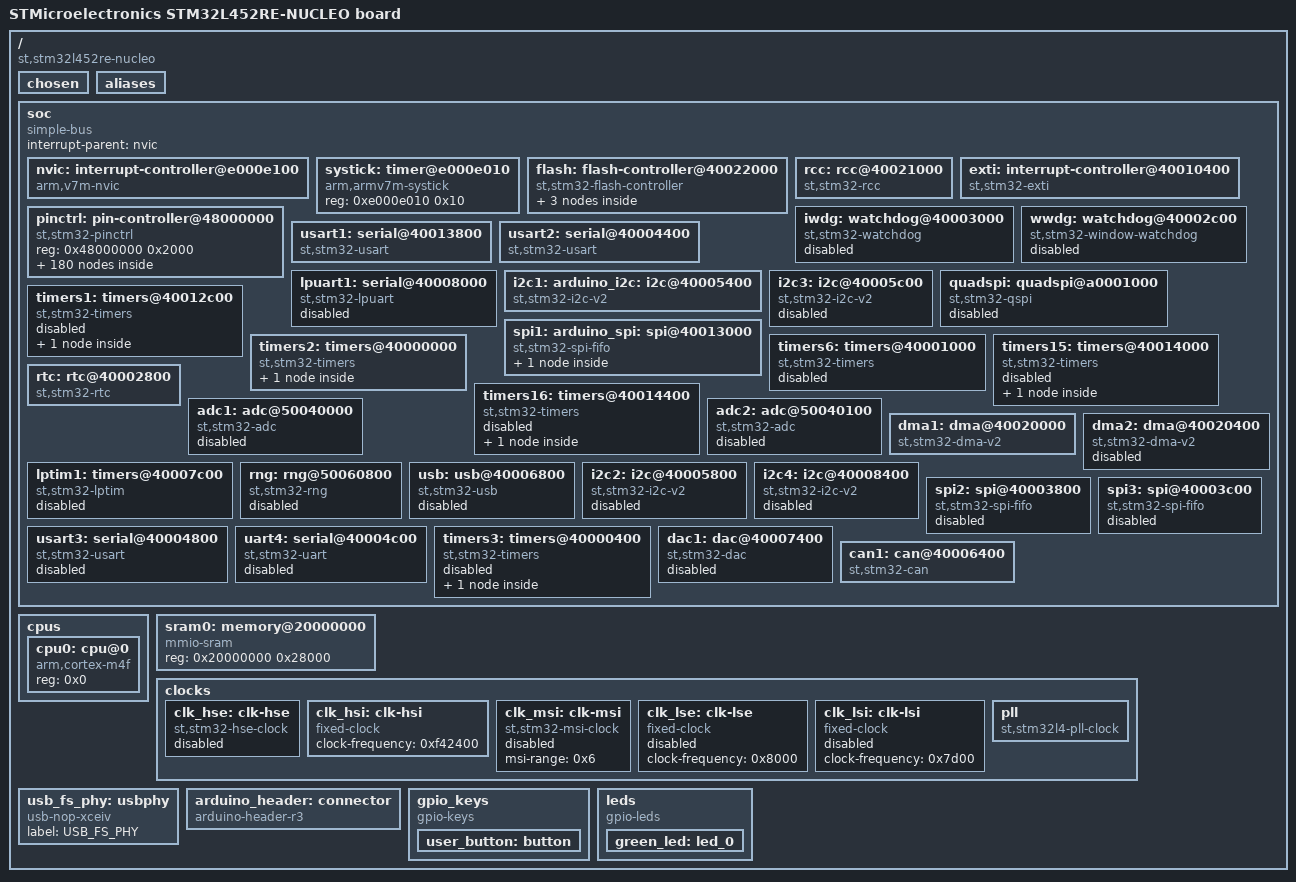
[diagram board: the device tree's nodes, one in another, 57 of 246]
/dts-v1/;

/ {
	#address-cells = < 0x1 >;
	#size-cells = < 0x1 >;
	model = "STMicroelectronics STM32L452RE-NUCLEO board";
	compatible = "st,stm32l452re-nucleo";
	chosen {
		zephyr,entropy = &rng;
		zephyr,flash-controller = &flash;
		zephyr,console = &usart2;
		zephyr,shell-uart = &usart2;
		zephyr,sram = &sram0;
		zephyr,flash = &flash0;
		zephyr,canbus = &can1;
	};
	aliases {
		sw0 = &user_button;
		led0 = &green_led;
	};
	soc {
		#address-cells = < 0x1 >;
		#size-cells = < 0x1 >;
		compatible = "simple-bus";
		interrupt-parent = < &nvic >;
		ranges;
		nvic: interrupt-controller@e000e100 {
			#address-cells = < 0x1 >;
			compatible = "arm,v7m-nvic";
			reg = < 0xe000e100 0xc00 >;
			interrupt-controller;
			#interrupt-cells = < 0x2 >;
			arm,num-irq-priority-bits = < 0x4 >;
			phandle = < 0x1 >;
		};
		systick: timer@e000e010 {
			compatible = "arm,armv7m-systick";
			reg = < 0xe000e010 0x10 >;
		};
		flash: flash-controller@40022000 {
			compatible = "st,stm32-flash-controller", "st,stm32l4-flash-controller";
			label = "FLASH_CTRL";
			reg = < 0x40022000 0x400 >;
			interrupts = < 0x4 0x0 >;
			clocks = < &rcc 0x0 0x100 >;
			#address-cells = < 0x1 >;
			#size-cells = < 0x1 >;
			flash0: flash@8000000 {
				compatible = "st,stm32-nv-flash", "soc-nv-flash";
				label = "FLASH_STM32";
				write-block-size = < 0x8 >;
				erase-block-size = < 0x800 >;
				max-erase-time = < 0x19 >;
				reg = < 0x8000000 0x80000 >;
				partitions {
					compatible = "fixed-partitions";
					#address-cells = < 0x1 >;
					#size-cells = < 0x1 >;
					storage_partition: partition@7c000 {
						label = "storage";
						reg = < 0x7c000 0x8000 >;
					};
				};
			};
		};
		rcc: rcc@40021000 {
			compatible = "st,stm32-rcc";
			#clock-cells = < 0x2 >;
			reg = < 0x40021000 0x400 >;
			clocks = < &pll >;
			clock-frequency = < 0x4c4b400 >;
			ahb-prescaler = < 0x1 >;
			apb1-prescaler = < 0x1 >;
			apb2-prescaler = < 0x1 >;
			status = "okay";
			phandle = < 0x2 >;
		};
		exti: interrupt-controller@40010400 {
			compatible = "st,stm32-exti";
			interrupt-controller;
			#interrupt-cells = < 0x1 >;
			reg = < 0x40010400 0x400 >;
		};
		pinctrl: pin-controller@48000000 {
			compatible = "st,stm32-pinctrl";
			#address-cells = < 0x1 >;
			#size-cells = < 0x1 >;
			reg = < 0x48000000 0x2000 >;
			gpioa: gpio@48000000 {
				compatible = "st,stm32-gpio";
				gpio-controller;
				#gpio-cells = < 0x2 >;
				reg = < 0x48000000 0x400 >;
				clocks = < &rcc 0x1 0x1 >;
				label = "GPIOA";
				phandle = < 0x15 >;
			};
			gpiob: gpio@48000400 {
				compatible = "st,stm32-gpio";
				gpio-controller;
				#gpio-cells = < 0x2 >;
				reg = < 0x48000400 0x400 >;
				clocks = < &rcc 0x1 0x2 >;
				label = "GPIOB";
				phandle = < 0xe >;
			};
			gpioc: gpio@48000800 {
				compatible = "st,stm32-gpio";
				gpio-controller;
				#gpio-cells = < 0x2 >;
				reg = < 0x48000800 0x400 >;
				clocks = < &rcc 0x1 0x4 >;
				label = "GPIOC";
				phandle = < 0xf >;
			};
			gpioh: gpio@48001c00 {
				compatible = "st,stm32-gpio";
				gpio-controller;
				#gpio-cells = < 0x2 >;
				reg = < 0x48001c00 0x400 >;
				clocks = < &rcc 0x1 0x80 >;
				label = "GPIOH";
			};
			gpiod: gpio@48000c00 {
				compatible = "st,stm32-gpio";
				gpio-controller;
				#gpio-cells = < 0x2 >;
				reg = < 0x48000c00 0x400 >;
				clocks = < &rcc 0x1 0x8 >;
				label = "GPIOD";
			};
			gpioe: gpio@48001000 {
				compatible = "st,stm32-gpio";
				gpio-controller;
				#gpio-cells = < 0x2 >;
				reg = < 0x48001000 0x400 >;
				clocks = < &rcc 0x1 0x10 >;
				label = "GPIOE";
			};
			adc1_in5_pa0: adc1_in5_pa0 {
				pinmux = < 0x10 >;
			};
			adc1_in6_pa1: adc1_in6_pa1 {
				pinmux = < 0x30 >;
			};
			adc1_in7_pa2: adc1_in7_pa2 {
				pinmux = < 0x50 >;
			};
			adc1_in8_pa3: adc1_in8_pa3 {
				pinmux = < 0x70 >;
			};
			adc1_in9_pa4: adc1_in9_pa4 {
				pinmux = < 0x90 >;
			};
			adc1_in10_pa5: adc1_in10_pa5 {
				pinmux = < 0xb0 >;
			};
			adc1_in11_pa6: adc1_in11_pa6 {
				pinmux = < 0xd0 >;
			};
			adc1_in12_pa7: adc1_in12_pa7 {
				pinmux = < 0xf0 >;
			};
			adc1_in15_pb0: adc1_in15_pb0 {
				pinmux = < 0x210 >;
			};
			adc1_in16_pb1: adc1_in16_pb1 {
				pinmux = < 0x230 >;
			};
			adc1_in1_pc0: adc1_in1_pc0 {
				pinmux = < 0x410 >;
			};
			adc1_in2_pc1: adc1_in2_pc1 {
				pinmux = < 0x430 >;
			};
			adc1_in3_pc2: adc1_in3_pc2 {
				pinmux = < 0x450 >;
			};
			adc1_in4_pc3: adc1_in4_pc3 {
				pinmux = < 0x470 >;
			};
			adc1_in13_pc4: adc1_in13_pc4 {
				pinmux = < 0x490 >;
			};
			adc1_in14_pc5: adc1_in14_pc5 {
				pinmux = < 0x4b0 >;
			};
			can1_rx_pa11: can1_rx_pa11 {
				pinmux = < 0x169 >;
				bias-pull-up;
				phandle = < 0x12 >;
			};
			can1_rx_pb5: can1_rx_pb5 {
				pinmux = < 0x2a3 >;
				bias-pull-up;
			};
			can1_rx_pb8: can1_rx_pb8 {
				pinmux = < 0x309 >;
				bias-pull-up;
			};
			can1_rx_pb12: can1_rx_pb12 {
				pinmux = < 0x38a >;
				bias-pull-up;
			};
			can1_tx_pa12: can1_tx_pa12 {
				pinmux = < 0x189 >;
				phandle = < 0x13 >;
			};
			can1_tx_pb6: can1_tx_pb6 {
				pinmux = < 0x2c8 >;
			};
			can1_tx_pb9: can1_tx_pb9 {
				pinmux = < 0x329 >;
			};
			can1_tx_pb13: can1_tx_pb13 {
				pinmux = < 0x3aa >;
			};
			dac1_out1_pa4: dac1_out1_pa4 {
				pinmux = < 0x90 >;
			};
			i2c1_scl_pa9: i2c1_scl_pa9 {
				pinmux = < 0x124 >;
				bias-pull-up;
				drive-open-drain;
			};
			i2c1_scl_pb6: i2c1_scl_pb6 {
				pinmux = < 0x2c4 >;
				bias-pull-up;
				drive-open-drain;
			};
			i2c1_scl_pb8: i2c1_scl_pb8 {
				pinmux = < 0x304 >;
				bias-pull-up;
				drive-open-drain;
				phandle = < 0x9 >;
			};
			i2c2_scl_pb10: i2c2_scl_pb10 {
				pinmux = < 0x344 >;
				bias-pull-up;
				drive-open-drain;
			};
			i2c2_scl_pb13: i2c2_scl_pb13 {
				pinmux = < 0x3a4 >;
				bias-pull-up;
				drive-open-drain;
			};
			i2c3_scl_pa7: i2c3_scl_pa7 {
				pinmux = < 0xe4 >;
				bias-pull-up;
				drive-open-drain;
			};
			i2c3_scl_pc0: i2c3_scl_pc0 {
				pinmux = < 0x404 >;
				bias-pull-up;
				drive-open-drain;
			};
			i2c4_scl_pb6: i2c4_scl_pb6 {
				pinmux = < 0x2c5 >;
				bias-pull-up;
				drive-open-drain;
			};
			i2c4_scl_pb10: i2c4_scl_pb10 {
				pinmux = < 0x343 >;
				bias-pull-up;
				drive-open-drain;
			};
			i2c4_scl_pc0: i2c4_scl_pc0 {
				pinmux = < 0x402 >;
				bias-pull-up;
				drive-open-drain;
			};
			i2c1_sda_pa10: i2c1_sda_pa10 {
				pinmux = < 0x144 >;
				bias-pull-up;
				drive-open-drain;
			};
			i2c1_sda_pb7: i2c1_sda_pb7 {
				pinmux = < 0x2e4 >;
				bias-pull-up;
				drive-open-drain;
				phandle = < 0xa >;
			};
			i2c1_sda_pb9: i2c1_sda_pb9 {
				pinmux = < 0x324 >;
				bias-pull-up;
				drive-open-drain;
			};
			i2c2_sda_pb11: i2c2_sda_pb11 {
				pinmux = < 0x364 >;
				bias-pull-up;
				drive-open-drain;
			};
			i2c2_sda_pb14: i2c2_sda_pb14 {
				pinmux = < 0x3c4 >;
				bias-pull-up;
				drive-open-drain;
			};
			i2c3_sda_pb4: i2c3_sda_pb4 {
				pinmux = < 0x284 >;
				bias-pull-up;
				drive-open-drain;
			};
			i2c3_sda_pc1: i2c3_sda_pc1 {
				pinmux = < 0x424 >;
				bias-pull-up;
				drive-open-drain;
			};
			i2c4_sda_pb7: i2c4_sda_pb7 {
				pinmux = < 0x2e5 >;
				bias-pull-up;
				drive-open-drain;
			};
			i2c4_sda_pb11: i2c4_sda_pb11 {
				pinmux = < 0x363 >;
				bias-pull-up;
				drive-open-drain;
			};
			i2c4_sda_pc1: i2c4_sda_pc1 {
				pinmux = < 0x422 >;
				bias-pull-up;
				drive-open-drain;
			};
			quadspi_bk1_ncs_pa2: quadspi_bk1_ncs_pa2 {
				pinmux = < 0x4a >;
				slew-rate = "very-high-speed";
			};
			quadspi_clk_pa3: quadspi_clk_pa3 {
				pinmux = < 0x6a >;
				slew-rate = "very-high-speed";
			};
			quadspi_bk1_io3_pa6: quadspi_bk1_io3_pa6 {
				pinmux = < 0xca >;
				slew-rate = "very-high-speed";
			};
			quadspi_bk1_io2_pa7: quadspi_bk1_io2_pa7 {
				pinmux = < 0xea >;
				slew-rate = "very-high-speed";
			};
			quadspi_bk1_io1_pb0: quadspi_bk1_io1_pb0 {
				pinmux = < 0x20a >;
				slew-rate = "very-high-speed";
			};
			quadspi_bk1_io0_pb1: quadspi_bk1_io0_pb1 {
				pinmux = < 0x22a >;
				slew-rate = "very-high-speed";
			};
			quadspi_clk_pb10: quadspi_clk_pb10 {
				pinmux = < 0x34a >;
				slew-rate = "very-high-speed";
			};
			quadspi_bk1_ncs_pb11: quadspi_bk1_ncs_pb11 {
				pinmux = < 0x36a >;
				slew-rate = "very-high-speed";
			};
			sdmmc1_d4_pb8: sdmmc1_d4_pb8 {
				pinmux = < 0x30c >;
				bias-pull-up;
				slew-rate = "very-high-speed";
			};
			sdmmc1_d5_pb9: sdmmc1_d5_pb9 {
				pinmux = < 0x32c >;
				bias-pull-up;
				slew-rate = "very-high-speed";
			};
			sdmmc1_d6_pc6: sdmmc1_d6_pc6 {
				pinmux = < 0x4cc >;
				bias-pull-up;
				slew-rate = "very-high-speed";
			};
			sdmmc1_d7_pc7: sdmmc1_d7_pc7 {
				pinmux = < 0x4ec >;
				bias-pull-up;
				slew-rate = "very-high-speed";
			};
			sdmmc1_d0_pc8: sdmmc1_d0_pc8 {
				pinmux = < 0x50c >;
				bias-pull-up;
				slew-rate = "very-high-speed";
			};
			sdmmc1_d1_pc9: sdmmc1_d1_pc9 {
				pinmux = < 0x52c >;
				bias-pull-up;
				slew-rate = "very-high-speed";
			};
			sdmmc1_d2_pc10: sdmmc1_d2_pc10 {
				pinmux = < 0x54c >;
				bias-pull-up;
				slew-rate = "very-high-speed";
			};
			sdmmc1_d3_pc11: sdmmc1_d3_pc11 {
				pinmux = < 0x56c >;
				bias-pull-up;
				slew-rate = "very-high-speed";
			};
			sdmmc1_ck_pc12: sdmmc1_ck_pc12 {
				pinmux = < 0x58c >;
				bias-pull-up;
				slew-rate = "very-high-speed";
			};
			sdmmc1_cmd_pd2: sdmmc1_cmd_pd2 {
				pinmux = < 0x64c >;
				bias-pull-up;
				slew-rate = "very-high-speed";
			};
			spi1_miso_pa6: spi1_miso_pa6 {
				pinmux = < 0xc5 >;
				bias-pull-down;
				phandle = < 0xc >;
			};
			spi1_miso_pa11: spi1_miso_pa11 {
				pinmux = < 0x165 >;
				bias-pull-down;
			};
			spi1_miso_pb4: spi1_miso_pb4 {
				pinmux = < 0x285 >;
				bias-pull-down;
			};
			spi2_miso_pb14: spi2_miso_pb14 {
				pinmux = < 0x3c5 >;
				bias-pull-down;
			};
			spi2_miso_pc2: spi2_miso_pc2 {
				pinmux = < 0x445 >;
				bias-pull-down;
			};
			spi3_miso_pb4: spi3_miso_pb4 {
				pinmux = < 0x286 >;
				bias-pull-down;
			};
			spi3_miso_pc11: spi3_miso_pc11 {
				pinmux = < 0x566 >;
				bias-pull-down;
			};
			spi1_mosi_pa7: spi1_mosi_pa7 {
				pinmux = < 0xe5 >;
				bias-pull-down;
				phandle = < 0xd >;
			};
			spi1_mosi_pa12: spi1_mosi_pa12 {
				pinmux = < 0x185 >;
				bias-pull-down;
			};
			spi1_mosi_pb5: spi1_mosi_pb5 {
				pinmux = < 0x2a5 >;
				bias-pull-down;
			};
			spi2_mosi_pb15: spi2_mosi_pb15 {
				pinmux = < 0x3e5 >;
				bias-pull-down;
			};
			spi2_mosi_pc3: spi2_mosi_pc3 {
				pinmux = < 0x465 >;
				bias-pull-down;
			};
			spi3_mosi_pb5: spi3_mosi_pb5 {
				pinmux = < 0x2a6 >;
				bias-pull-down;
			};
			spi3_mosi_pc12: spi3_mosi_pc12 {
				pinmux = < 0x586 >;
				bias-pull-down;
			};
			spi1_nss_pa4: spi1_nss_pa4 {
				pinmux = < 0x85 >;
				bias-pull-up;
			};
			spi1_nss_pa15: spi1_nss_pa15 {
				pinmux = < 0x1e5 >;
				bias-pull-up;
			};
			spi1_nss_pb0: spi1_nss_pb0 {
				pinmux = < 0x205 >;
				bias-pull-up;
			};
			spi2_nss_pb9: spi2_nss_pb9 {
				pinmux = < 0x325 >;
				bias-pull-up;
			};
			spi2_nss_pb12: spi2_nss_pb12 {
				pinmux = < 0x385 >;
				bias-pull-up;
			};
			spi3_nss_pa4: spi3_nss_pa4 {
				pinmux = < 0x86 >;
				bias-pull-up;
			};
			spi3_nss_pa15: spi3_nss_pa15 {
				pinmux = < 0x1e6 >;
				bias-pull-up;
			};
			spi1_sck_pa1: spi1_sck_pa1 {
				pinmux = < 0x25 >;
				bias-pull-down;
				slew-rate = "very-high-speed";
			};
			spi1_sck_pa5: spi1_sck_pa5 {
				pinmux = < 0xa5 >;
				bias-pull-down;
				slew-rate = "very-high-speed";
				phandle = < 0xb >;
			};
			spi1_sck_pb3: spi1_sck_pb3 {
				pinmux = < 0x265 >;
				bias-pull-down;
				slew-rate = "very-high-speed";
			};
			spi2_sck_pb10: spi2_sck_pb10 {
				pinmux = < 0x345 >;
				bias-pull-down;
				slew-rate = "very-high-speed";
			};
			spi2_sck_pb13: spi2_sck_pb13 {
				pinmux = < 0x3a5 >;
				bias-pull-down;
				slew-rate = "very-high-speed";
			};
			spi3_sck_pb3: spi3_sck_pb3 {
				pinmux = < 0x266 >;
				bias-pull-down;
				slew-rate = "very-high-speed";
			};
			spi3_sck_pc10: spi3_sck_pc10 {
				pinmux = < 0x546 >;
				bias-pull-down;
				slew-rate = "very-high-speed";
			};
			tim1_ch1n_pa7: tim1_ch1n_pa7 {
				pinmux = < 0xe1 >;
			};
			tim1_ch1_pa8: tim1_ch1_pa8 {
				pinmux = < 0x101 >;
			};
			tim1_ch2_pa9: tim1_ch2_pa9 {
				pinmux = < 0x121 >;
			};
			tim1_ch3_pa10: tim1_ch3_pa10 {
				pinmux = < 0x141 >;
			};
			tim1_ch4_pa11: tim1_ch4_pa11 {
				pinmux = < 0x161 >;
			};
			tim1_ch2n_pb0: tim1_ch2n_pb0 {
				pinmux = < 0x201 >;
			};
			tim1_ch3n_pb1: tim1_ch3n_pb1 {
				pinmux = < 0x221 >;
			};
			tim1_ch1n_pb13: tim1_ch1n_pb13 {
				pinmux = < 0x3a1 >;
			};
			tim1_ch2n_pb14: tim1_ch2n_pb14 {
				pinmux = < 0x3c1 >;
			};
			tim1_ch3n_pb15: tim1_ch3n_pb15 {
				pinmux = < 0x3e1 >;
			};
			tim2_ch1_pa0: tim2_ch1_pa0 {
				pinmux = < 0x1 >;
				phandle = < 0x10 >;
			};
			tim2_ch2_pa1: tim2_ch2_pa1 {
				pinmux = < 0x21 >;
			};
			tim2_ch3_pa2: tim2_ch3_pa2 {
				pinmux = < 0x41 >;
			};
			tim2_ch4_pa3: tim2_ch4_pa3 {
				pinmux = < 0x61 >;
			};
			tim2_ch1_pa5: tim2_ch1_pa5 {
				pinmux = < 0xa1 >;
			};
			tim2_ch1_pa15: tim2_ch1_pa15 {
				pinmux = < 0x1e1 >;
			};
			tim2_ch2_pb3: tim2_ch2_pb3 {
				pinmux = < 0x261 >;
			};
			tim2_ch3_pb10: tim2_ch3_pb10 {
				pinmux = < 0x341 >;
			};
			tim2_ch4_pb11: tim2_ch4_pb11 {
				pinmux = < 0x361 >;
			};
			tim3_ch1_pa6: tim3_ch1_pa6 {
				pinmux = < 0xc2 >;
			};
			tim3_ch2_pa7: tim3_ch2_pa7 {
				pinmux = < 0xe2 >;
			};
			tim3_ch3_pb0: tim3_ch3_pb0 {
				pinmux = < 0x202 >;
			};
			tim3_ch4_pb1: tim3_ch4_pb1 {
				pinmux = < 0x222 >;
			};
			tim3_ch1_pb4: tim3_ch1_pb4 {
				pinmux = < 0x282 >;
			};
			tim3_ch2_pb5: tim3_ch2_pb5 {
				pinmux = < 0x2a2 >;
			};
			tim3_ch1_pc6: tim3_ch1_pc6 {
				pinmux = < 0x4c2 >;
			};
			tim3_ch2_pc7: tim3_ch2_pc7 {
				pinmux = < 0x4e2 >;
			};
			tim3_ch3_pc8: tim3_ch3_pc8 {
				pinmux = < 0x502 >;
			};
			tim3_ch4_pc9: tim3_ch4_pc9 {
				pinmux = < 0x522 >;
			};
			tim15_ch1n_pa1: tim15_ch1n_pa1 {
				pinmux = < 0x2e >;
			};
			tim15_ch1_pa2: tim15_ch1_pa2 {
				pinmux = < 0x4e >;
			};
			tim15_ch2_pa3: tim15_ch2_pa3 {
				pinmux = < 0x6e >;
			};
			tim15_ch1n_pb13: tim15_ch1n_pb13 {
				pinmux = < 0x3ae >;
			};
			tim15_ch1_pb14: tim15_ch1_pb14 {
				pinmux = < 0x3ce >;
			};
			tim15_ch2_pb15: tim15_ch2_pb15 {
				pinmux = < 0x3ee >;
			};
			tim16_ch1_pa6: tim16_ch1_pa6 {
				pinmux = < 0xce >;
			};
			tim16_ch1n_pb6: tim16_ch1n_pb6 {
				pinmux = < 0x2ce >;
			};
			tim16_ch1_pb8: tim16_ch1_pb8 {
				pinmux = < 0x30e >;
			};
			lpuart1_cts_pa6: lpuart1_cts_pa6 {
				pinmux = < 0xc8 >;
				bias-pull-up;
				drive-open-drain;
			};
			usart1_cts_pa11: usart1_cts_pa11 {
				pinmux = < 0x167 >;
				bias-pull-up;
				drive-open-drain;
			};
			usart1_cts_pb4: usart1_cts_pb4 {
				pinmux = < 0x287 >;
				bias-pull-up;
				drive-open-drain;
			};
			lpuart1_cts_pb13: lpuart1_cts_pb13 {
				pinmux = < 0x3a8 >;
				bias-pull-up;
				drive-open-drain;
			};
			usart2_cts_pa0: usart2_cts_pa0 {
				pinmux = < 0x7 >;
				bias-pull-up;
				drive-open-drain;
			};
			usart3_cts_pa6: usart3_cts_pa6 {
				pinmux = < 0xc7 >;
				bias-pull-up;
				drive-open-drain;
			};
			usart3_cts_pb13: usart3_cts_pb13 {
				pinmux = < 0x3a7 >;
				bias-pull-up;
				drive-open-drain;
			};
			uart4_cts_pb7: uart4_cts_pb7 {
				pinmux = < 0x2e8 >;
				bias-pull-up;
				drive-open-drain;
			};
			usart1_rts_pa12: usart1_rts_pa12 {
				pinmux = < 0x187 >;
				bias-pull-up;
				drive-open-drain;
			};
			lpuart1_rts_pb1: lpuart1_rts_pb1 {
				pinmux = < 0x228 >;
				bias-pull-up;
				drive-open-drain;
			};
			usart1_rts_pb3: usart1_rts_pb3 {
				pinmux = < 0x267 >;
				bias-pull-up;
				drive-open-drain;
			};
			lpuart1_rts_pb12: lpuart1_rts_pb12 {
				pinmux = < 0x388 >;
				bias-pull-up;
				drive-open-drain;
			};
			usart2_rts_pa1: usart2_rts_pa1 {
				pinmux = < 0x27 >;
				bias-pull-up;
				drive-open-drain;
			};
			usart3_rts_pa15: usart3_rts_pa15 {
				pinmux = < 0x1e7 >;
				bias-pull-up;
				drive-open-drain;
			};
			usart3_rts_pb1: usart3_rts_pb1 {
				pinmux = < 0x227 >;
				bias-pull-up;
				drive-open-drain;
			};
			usart3_rts_pb14: usart3_rts_pb14 {
				pinmux = < 0x3c7 >;
				bias-pull-up;
				drive-open-drain;
			};
			usart3_rts_pd2: usart3_rts_pd2 {
				pinmux = < 0x647 >;
				bias-pull-up;
				drive-open-drain;
			};
			uart4_rts_pa15: uart4_rts_pa15 {
				pinmux = < 0x1e8 >;
				bias-pull-up;
				drive-open-drain;
			};
			lpuart1_rx_pa3: lpuart1_rx_pa3 {
				pinmux = < 0x68 >;
			};
			usart1_rx_pa10: usart1_rx_pa10 {
				pinmux = < 0x147 >;
				phandle = < 0x5 >;
			};
			usart1_rx_pb7: usart1_rx_pb7 {
				pinmux = < 0x2e7 >;
			};
			lpuart1_rx_pb10: lpuart1_rx_pb10 {
				pinmux = < 0x348 >;
			};
			lpuart1_rx_pc0: lpuart1_rx_pc0 {
				pinmux = < 0x408 >;
			};
			usart2_rx_pa3: usart2_rx_pa3 {
				pinmux = < 0x67 >;
				phandle = < 0x8 >;
			};
			usart2_rx_pa15: usart2_rx_pa15 {
				pinmux = < 0x1e3 >;
			};
			usart3_rx_pb11: usart3_rx_pb11 {
				pinmux = < 0x367 >;
			};
			usart3_rx_pc5: usart3_rx_pc5 {
				pinmux = < 0x4a7 >;
			};
			usart3_rx_pc11: usart3_rx_pc11 {
				pinmux = < 0x567 >;
			};
			uart4_rx_pa1: uart4_rx_pa1 {
				pinmux = < 0x28 >;
			};
			uart4_rx_pc11: uart4_rx_pc11 {
				pinmux = < 0x568 >;
			};
			lpuart1_tx_pa2: lpuart1_tx_pa2 {
				pinmux = < 0x48 >;
				bias-pull-up;
			};
			usart1_tx_pa9: usart1_tx_pa9 {
				pinmux = < 0x127 >;
				bias-pull-up;
				phandle = < 0x4 >;
			};
			usart1_tx_pb6: usart1_tx_pb6 {
				pinmux = < 0x2c7 >;
				bias-pull-up;
			};
			lpuart1_tx_pb11: lpuart1_tx_pb11 {
				pinmux = < 0x368 >;
				bias-pull-up;
			};
			lpuart1_tx_pc1: lpuart1_tx_pc1 {
				pinmux = < 0x428 >;
				bias-pull-up;
			};
			usart2_tx_pa2: usart2_tx_pa2 {
				pinmux = < 0x47 >;
				bias-pull-up;
				phandle = < 0x7 >;
			};
			usart3_tx_pb10: usart3_tx_pb10 {
				pinmux = < 0x347 >;
				bias-pull-up;
			};
			usart3_tx_pc4: usart3_tx_pc4 {
				pinmux = < 0x487 >;
				bias-pull-up;
			};
			usart3_tx_pc10: usart3_tx_pc10 {
				pinmux = < 0x547 >;
				bias-pull-up;
			};
			uart4_tx_pa0: uart4_tx_pa0 {
				pinmux = < 0x8 >;
				bias-pull-up;
			};
			uart4_tx_pc10: uart4_tx_pc10 {
				pinmux = < 0x548 >;
				bias-pull-up;
			};
			usb_dm_pa11: usb_dm_pa11 {
				pinmux = < 0x16a >;
			};
			usb_dp_pa12: usb_dp_pa12 {
				pinmux = < 0x18a >;
			};
			usb_noe_pa13: usb_noe_pa13 {
				pinmux = < 0x1aa >;
			};
			usb_noe_pc9: usb_noe_pc9 {
				pinmux = < 0x52a >;
			};
		};
		iwdg: watchdog@40003000 {
			compatible = "st,stm32-watchdog";
			reg = < 0x40003000 0x400 >;
			label = "IWDG";
			status = "disabled";
		};
		wwdg: watchdog@40002c00 {
			compatible = "st,stm32-window-watchdog";
			reg = < 0x40002c00 0x400 >;
			clocks = < &rcc 0x2 0x800 >;
			label = "WWDG";
			interrupts = < 0x0 0x7 >;
			status = "disabled";
		};
		usart1: serial@40013800 {
			compatible = "st,stm32-usart", "st,stm32-uart";
			reg = < 0x40013800 0x400 >;
			clocks = < &rcc 0x3 0x4000 >;
			interrupts = < 0x25 0x0 >;
			status = "okay";
			label = "UART_1";
			pinctrl-0 = < &usart1_tx_pa9 &usart1_rx_pa10 >;
			pinctrl-names = "default";
			current-speed = < 0x1c200 >;
			parity = "none";
			dmas = < &dma1 0x4 0x2 0x20440 >, < &dma1 0x5 0x2 0x20480 >;
			dma-names = "tx", "rx";
		};
		usart2: serial@40004400 {
			compatible = "st,stm32-usart", "st,stm32-uart";
			reg = < 0x40004400 0x400 >;
			clocks = < &rcc 0x2 0x20000 >;
			interrupts = < 0x26 0x0 >;
			status = "okay";
			label = "UART_2";
			pinctrl-0 = < &usart2_tx_pa2 &usart2_rx_pa3 >;
			pinctrl-names = "default";
			current-speed = < 0x1c200 >;
		};
		lpuart1: serial@40008000 {
			compatible = "st,stm32-lpuart", "st,stm32-uart";
			reg = < 0x40008000 0x400 >;
			clocks = < &rcc 0x4 0x1 >;
			interrupts = < 0x46 0x0 >;
			status = "disabled";
			label = "LPUART_1";
		};
		i2c1: arduino_i2c: i2c@40005400 {
			compatible = "st,stm32-i2c-v2";
			clock-frequency = < 0x61a80 >;
			#address-cells = < 0x1 >;
			#size-cells = < 0x0 >;
			reg = < 0x40005400 0x400 >;
			clocks = < &rcc 0x2 0x200000 >;
			interrupts = < 0x1f 0x0 >, < 0x20 0x0 >;
			interrupt-names = "event", "error";
			status = "okay";
			label = "I2C_1";
			pinctrl-0 = < &i2c1_scl_pb8 &i2c1_sda_pb7 >;
			pinctrl-names = "default";
		};
		i2c3: i2c@40005c00 {
			compatible = "st,stm32-i2c-v2";
			clock-frequency = < 0x186a0 >;
			#address-cells = < 0x1 >;
			#size-cells = < 0x0 >;
			reg = < 0x40005c00 0x400 >;
			clocks = < &rcc 0x2 0x800000 >;
			interrupts = < 0x48 0x0 >, < 0x49 0x0 >;
			interrupt-names = "event", "error";
			status = "disabled";
			label = "I2C_3";
		};
		quadspi: quadspi@a0001000 {
			compatible = "st,stm32-qspi";
			#address-cells = < 0x1 >;
			#size-cells = < 0x0 >;
			reg = < 0xa0001000 0x400 >;
			interrupts = < 0x47 0x0 >;
			clocks = < &rcc 0x6 0x100 >;
			status = "disabled";
			label = "QUADSPI";
		};
		spi1: arduino_spi: spi@40013000 {
			compatible = "st,stm32-spi-fifo", "st,stm32-spi";
			#address-cells = < 0x1 >;
			#size-cells = < 0x0 >;
			reg = < 0x40013000 0x400 >;
			interrupts = < 0x23 0x5 >;
			clocks = < &rcc 0x3 0x1000 >;
			status = "okay";
			label = "SPI_1";
			pinctrl-0 = < &spi1_sck_pa5 &spi1_miso_pa6 &spi1_mosi_pa7 >;
			pinctrl-names = "default";
			cs-gpios = < &gpiob 0x6 0x1 >;
			lora0: sx1278@0 {
				compatible = "semtech,sx1276";
				reg = < 0x0 >;
				label = "sx1278";
				reset-gpios = < &gpiob 0x0 0x7 >;
				dio-gpios = < &gpioc 0x0 0x20 >, < &gpioc 0x1 0x20 >, < &gpioc 0x2 0x20 >, < &gpioc 0x3 0x20 >;
				power-amplifier-output = "pa-boost";
				spi-max-frequency = < 0x7a120 >;
			};
		};
		timers1: timers@40012c00 {
			compatible = "st,stm32-timers";
			reg = < 0x40012c00 0x400 >;
			clocks = < &rcc 0x3 0x800 >;
			interrupts = < 0x18 0x0 >, < 0x19 0x0 >, < 0x1a 0x0 >, < 0x1b 0x0 >;
			interrupt-names = "brk", "up", "trgcom", "cc";
			st,prescaler = < 0x0 >;
			status = "disabled";
			label = "TIMERS_1";
			pwm {
				compatible = "st,stm32-pwm";
				status = "disabled";
				label = "PWM_1";
				#pwm-cells = < 0x3 >;
			};
		};
		timers2: timers@40000000 {
			compatible = "st,stm32-timers";
			reg = < 0x40000000 0x400 >;
			clocks = < &rcc 0x2 0x1 >;
			interrupts = < 0x1c 0x0 >;
			interrupt-names = "global";
			st,prescaler = < 0x0 >;
			status = "okay";
			label = "TIMERS_2";
			pwm2: pwm {
				compatible = "st,stm32-pwm";
				status = "okay";
				label = "PWM_2";
				#pwm-cells = < 0x3 >;
				pinctrl-0 = < &tim2_ch1_pa0 >;
				pinctrl-names = "default";
			};
		};
		timers6: timers@40001000 {
			compatible = "st,stm32-timers";
			reg = < 0x40001000 0x400 >;
			clocks = < &rcc 0x2 0x10 >;
			interrupts = < 0x36 0x0 >;
			interrupt-names = "global";
			st,prescaler = < 0x0 >;
			status = "disabled";
			label = "TIMERS_6";
		};
		timers15: timers@40014000 {
			compatible = "st,stm32-timers";
			reg = < 0x40014000 0x400 >;
			clocks = < &rcc 0x3 0x10000 >;
			interrupts = < 0x18 0x0 >;
			interrupt-names = "global";
			st,prescaler = < 0x0 >;
			status = "disabled";
			label = "TIMERS_15";
			pwm {
				compatible = "st,stm32-pwm";
				status = "disabled";
				label = "PWM_15";
				#pwm-cells = < 0x3 >;
			};
		};
		timers16: timers@40014400 {
			compatible = "st,stm32-timers";
			reg = < 0x40014400 0x400 >;
			clocks = < &rcc 0x3 0x20000 >;
			interrupts = < 0x19 0x0 >;
			interrupt-names = "global";
			st,prescaler = < 0x0 >;
			status = "disabled";
			label = "TIMERS_16";
			pwm {
				compatible = "st,stm32-pwm";
				status = "disabled";
				label = "PWM_16";
				#pwm-cells = < 0x3 >;
			};
		};
		rtc: rtc@40002800 {
			compatible = "st,stm32-rtc";
			reg = < 0x40002800 0x400 >;
			interrupts = < 0x29 0x0 >;
			clocks = < &rcc 0x2 0x10000000 >;
			prescaler = < 0x8000 >;
			status = "okay";
			label = "RTC_0";
		};
		adc1: adc@50040000 {
			compatible = "st,stm32-adc";
			reg = < 0x50040000 0x100 >;
			clocks = < &rcc 0x1 0x2000 >;
			interrupts = < 0x12 0x0 >;
			status = "disabled";
			label = "ADC_1";
			#io-channel-cells = < 0x1 >;
		};
		adc2: adc@50040100 {
			compatible = "st,stm32-adc";
			reg = < 0x50040100 0x100 >;
			clocks = < &rcc 0x1 0x2000 >;
			interrupts = < 0x12 0x0 >;
			status = "disabled";
			label = "ADC_2";
			#io-channel-cells = < 0x1 >;
		};
		dma1: dma@40020000 {
			compatible = "st,stm32-dma-v2";
			#dma-cells = < 0x3 >;
			reg = < 0x40020000 0x400 >;
			interrupts = < 0xb 0x0 0xc 0x0 0xd 0x0 0xe 0x0 0xf 0x0 0x10 0x0 0x11 0x0 >;
			clocks = < &rcc 0x0 0x1 >;
			dma-requests = < 0x7 >;
			status = "okay";
			label = "DMA_1";
			phandle = < 0x6 >;
		};
		dma2: dma@40020400 {
			compatible = "st,stm32-dma-v2";
			#dma-cells = < 0x3 >;
			reg = < 0x40020400 0x400 >;
			interrupts = < 0x38 0x0 0x39 0x0 0x3a 0x0 0x3b 0x0 0x3c 0x0 0x44 0x0 0x45 0x0 >;
			clocks = < &rcc 0x0 0x2 >;
			dma-requests = < 0x7 >;
			status = "disabled";
			label = "DMA_2";
		};
		lptim1: timers@40007c00 {
			compatible = "st,stm32-lptim";
			clocks = < &rcc 0x2 0x80000000 >;
			#address-cells = < 0x1 >;
			#size-cells = < 0x0 >;
			reg = < 0x40007c00 0x400 >;
			interrupts = < 0x41 0x1 >;
			interrupt-names = "wakeup";
			status = "disabled";
			label = "LPTIM_1";
		};
		rng: rng@50060800 {
			compatible = "st,stm32-rng";
			reg = < 0x50060800 0x400 >;
			interrupts = < 0x50 0x0 >;
			clocks = < &rcc 0x1 0x40000 >;
			status = "disabled";
			label = "RNG";
		};
		usb: usb@40006800 {
			compatible = "st,stm32-usb";
			reg = < 0x40006800 0x40000 >;
			interrupts = < 0x43 0x0 >;
			interrupt-names = "usb";
			num-bidir-endpoints = < 0x8 >;
			ram-size = < 0x400 >;
			maximum-speed = "full-speed";
			phys = < &usb_fs_phy >;
			clocks = < &rcc 0x2 0x4000000 >;
			status = "disabled";
			label = "USB";
		};
		i2c2: i2c@40005800 {
			compatible = "st,stm32-i2c-v2";
			clock-frequency = < 0x186a0 >;
			#address-cells = < 0x1 >;
			#size-cells = < 0x0 >;
			reg = < 0x40005800 0x400 >;
			clocks = < &rcc 0x2 0x400000 >;
			interrupts = < 0x21 0x0 >, < 0x22 0x0 >;
			interrupt-names = "event", "error";
			status = "disabled";
			label = "I2C_2";
		};
		i2c4: i2c@40008400 {
			compatible = "st,stm32-i2c-v2";
			clock-frequency = < 0x186a0 >;
			#address-cells = < 0x1 >;
			#size-cells = < 0x0 >;
			reg = < 0x40008400 0x400 >;
			clocks = < &rcc 0x4 0x2 >;
			interrupts = < 0x53 0x0 >, < 0x54 0x0 >;
			interrupt-names = "event", "error";
			status = "disabled";
			label = "I2C_4";
		};
		spi2: spi@40003800 {
			compatible = "st,stm32-spi-fifo", "st,stm32-spi";
			#address-cells = < 0x1 >;
			#size-cells = < 0x0 >;
			reg = < 0x40003800 0x400 >;
			clocks = < &rcc 0x2 0x4000 >;
			interrupts = < 0x24 0x5 >;
			status = "disabled";
			label = "SPI_2";
		};
		spi3: spi@40003c00 {
			compatible = "st,stm32-spi-fifo", "st,stm32-spi";
			#address-cells = < 0x1 >;
			#size-cells = < 0x0 >;
			reg = < 0x40003c00 0x400 >;
			clocks = < &rcc 0x2 0x8000 >;
			interrupts = < 0x33 0x5 >;
			status = "disabled";
			label = "SPI_3";
		};
		usart3: serial@40004800 {
			compatible = "st,stm32-usart", "st,stm32-uart";
			reg = < 0x40004800 0x400 >;
			clocks = < &rcc 0x2 0x40000 >;
			interrupts = < 0x27 0x0 >;
			status = "disabled";
			label = "UART_3";
		};
		uart4: serial@40004c00 {
			compatible = "st,stm32-uart";
			reg = < 0x40004c00 0x400 >;
			clocks = < &rcc 0x2 0x80000 >;
			interrupts = < 0x34 0x0 >;
			status = "disabled";
			label = "UART_4";
		};
		timers3: timers@40000400 {
			compatible = "st,stm32-timers";
			reg = < 0x40000400 0x400 >;
			clocks = < &rcc 0x2 0x2 >;
			interrupts = < 0x1d 0x0 >;
			interrupt-names = "global";
			st,prescaler = < 0x0 >;
			status = "disabled";
			label = "TIMERS_3";
			pwm {
				compatible = "st,stm32-pwm";
				status = "disabled";
				label = "PWM_3";
				#pwm-cells = < 0x3 >;
			};
		};
		dac1: dac@40007400 {
			compatible = "st,stm32-dac";
			reg = < 0x40007400 0x400 >;
			clocks = < &rcc 0x2 0x20000000 >;
			status = "disabled";
			label = "DAC_1";
			#io-channel-cells = < 0x1 >;
		};
		can1: can@40006400 {
			compatible = "st,stm32-can";
			reg = < 0x40006400 0x400 >;
			interrupts = < 0x13 0x0 >, < 0x14 0x0 >, < 0x15 0x0 >, < 0x16 0x0 >;
			interrupt-names = "TX", "RX0", "RX1", "SCE";
			clocks = < &rcc 0x2 0x2000000 >;
			status = "okay";
			label = "CAN_1";
			bus-speed = < 0x1e848 >;
			sjw = < 0x1 >;
			prop-seg = < 0x0 >;
			phase-seg1 = < 0x4 >;
			phase-seg2 = < 0x5 >;
			pinctrl-0 = < &can1_rx_pa11 &can1_tx_pa12 >;
			pinctrl-names = "default";
		};
	};
	cpus {
		#address-cells = < 0x1 >;
		#size-cells = < 0x0 >;
		cpu0: cpu@0 {
			device_type = "cpu";
			compatible = "arm,cortex-m4f";
			reg = < 0x0 >;
		};
	};
	sram0: memory@20000000 {
		compatible = "mmio-sram";
		reg = < 0x20000000 0x28000 >;
	};
	clocks {
		clk_hse: clk-hse {
			#clock-cells = < 0x0 >;
			compatible = "st,stm32-hse-clock";
			status = "disabled";
		};
		clk_hsi: clk-hsi {
			#clock-cells = < 0x0 >;
			compatible = "fixed-clock";
			clock-frequency = < 0xf42400 >;
			status = "okay";
			phandle = < 0x14 >;
		};
		clk_msi: clk-msi {
			#clock-cells = < 0x0 >;
			compatible = "st,stm32-msi-clock";
			msi-range = < 0x6 >;
			status = "disabled";
		};
		clk_lse: clk-lse {
			#clock-cells = < 0x0 >;
			compatible = "fixed-clock";
			clock-frequency = < 0x8000 >;
			status = "disabled";
		};
		clk_lsi: clk-lsi {
			#clock-cells = < 0x0 >;
			compatible = "fixed-clock";
			clock-frequency = < 0x7d00 >;
			status = "disabled";
		};
		pll: pll {
			#clock-cells = < 0x0 >;
			compatible = "st,stm32l4-pll-clock";
			status = "okay";
			div-m = < 0x1 >;
			mul-n = < 0x14 >;
			div-p = < 0x7 >;
			div-q = < 0x2 >;
			div-r = < 0x4 >;
			clocks = < &clk_hsi >;
			phandle = < 0x3 >;
		};
	};
	usb_fs_phy: usbphy {
		compatible = "usb-nop-xceiv";
		#phy-cells = < 0x0 >;
		label = "USB_FS_PHY";
		phandle = < 0x11 >;
	};
	arduino_header: connector {
		compatible = "arduino-header-r3";
		#gpio-cells = < 0x2 >;
		gpio-map-mask = < 0xffffffff 0xffffffc0 >;
		gpio-map-pass-thru = < 0x0 0x3f >;
		gpio-map = < 0x0 0x0 &gpioa 0x0 0x0 >, < 0x1 0x0 &gpioa 0x1 0x0 >, < 0x2 0x0 &gpioa 0x4 0x0 >, < 0x3 0x0 &gpiob 0x0 0x0 >, < 0x4 0x0 &gpioc 0x1 0x0 >, < 0x5 0x0 &gpioc 0x0 0x0 >, < 0x6 0x0 &gpioa 0x3 0x0 >, < 0x7 0x0 &gpioa 0x2 0x0 >, < 0x8 0x0 &gpioa 0xa 0x0 >, < 0x9 0x0 &gpiob 0x3 0x0 >, < 0xa 0x0 &gpiob 0x5 0x0 >, < 0xb 0x0 &gpiob 0x4 0x0 >, < 0xc 0x0 &gpiob 0xa 0x0 >, < 0xd 0x0 &gpioa 0x8 0x0 >, < 0xe 0x0 &gpioa 0x9 0x0 >, < 0xf 0x0 &gpioc 0x7 0x0 >, < 0x10 0x0 &gpiob 0x6 0x0 >, < 0x11 0x0 &gpioa 0x7 0x0 >, < 0x12 0x0 &gpioa 0x6 0x0 >, < 0x13 0x0 &gpioa 0x5 0x0 >, < 0x14 0x0 &gpiob 0x9 0x0 >, < 0x15 0x0 &gpiob 0x8 0x0 >;
	};
	gpio_keys {
		compatible = "gpio-keys";
		user_button: button {
			label = "User";
			gpios = < &gpioc 0xd 0x1 >;
		};
	};
	leds {
		compatible = "gpio-leds";
		green_led: led_0 {
			gpios = < &gpioa 0x5 0x0 >;
			label = "User LD2";
		};
	};
};
